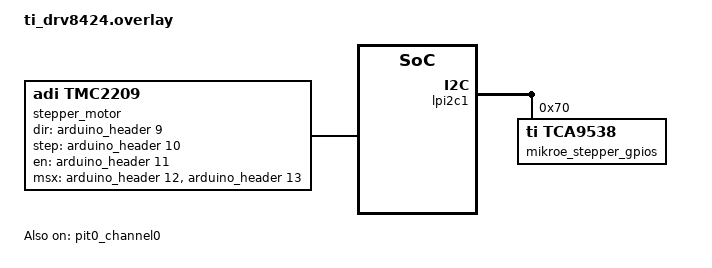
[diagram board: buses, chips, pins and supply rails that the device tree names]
/*
 * Copyright (c) 2024 Navimatix GmbH
 * SPDX-License-Identifier: Apache-2.0
 */

#include <zephyr/dt-bindings/gpio/gpio.h>

&lpi2c1 {
	status = "okay";

	mikroe_stepper_gpios: mikroe_stepper_ctrl_tca9538a@70 {
		status = "okay";
		compatible = "ti,tca9538";

		reg = <0x70>;

		gpio-controller;
		ngpios = <8>;
		#gpio-cells = <2>;

		gpio-reserved-ranges = <7 1>;

		gpio-line-names =
			"M0",
			"M1",
			"DEC0",
			"DEC1",
			"TOFF",
			"STP",
			"DIR";
	};
};

/ {

	stepper_motor: stepper_motor {
		status = "okay";
		compatible = "adi,tmc2209";
		micro-step-res = <8>;

		dir-gpios = <&arduino_header 9 0>; /* D3 */
		step-gpios = <&arduino_header 10 0>; /* D4 */
		en-gpios  = <&arduino_header 11 0>; /* D5 */
		msx-gpios = <&arduino_header 12 GPIO_ACTIVE_HIGH>,
			    <&arduino_header 13 GPIO_ACTIVE_HIGH>;

		timing-source = "counter-accel";

		counter = <&pit0_channel0>;
		acceleration = <50>;

		/* Note that this is the default value and this entry is only here as a showcase */
		accurate-steps = <15>;
	};
};

&pit0_channel0 {
	status = "okay";
};
